# PCIE1_CORE_VMAP_MMRS register map
Vendor: Texas Instruments
Peripheral module from a debugger description file (folder J7VCL).
Registers are 32-bit, read-write, reset 0x0 unless marked. A register's access mark holds for its fields unless they carry their own. Offsets are as the file gives them; lines under a group give offsets from that group; [hi:lo] are bit positions; {n}, {i} and the like mark numbered series; 'fields as' and 'values as' point back to an identical list; <NAME> marks a mode.

## PCIE1_CORE_VMAP_MMRS
0x00 PCIE_VMAP_CTRL_j — Control register Offset = 0h + (j * Ch); where j = 0h to 1Fh
  [0] EN — ID enable
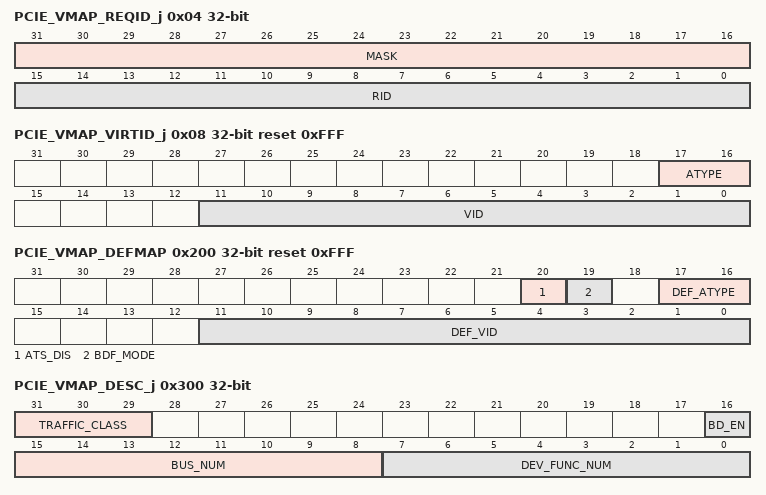
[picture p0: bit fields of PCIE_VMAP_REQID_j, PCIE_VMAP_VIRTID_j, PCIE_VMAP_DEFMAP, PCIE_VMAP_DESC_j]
0x04 PCIE_VMAP_REQID_j — Requester ID mask and value register Offset = 4h + (j * Ch); where j = 0h to 1Fh
  [31:16] MASK — RequesterID mask
  [15:0] RID — RequesterID
0x08 PCIE_VMAP_VIRTID_j reset 0xFFF — Virt ID and Atype register Offset = 8h + (j * Ch); where j = 0h to 1Fh
  [17:16] ATYPE — Address type attribute.
  [11:0] VID — Match ID
0x200 PCIE_VMAP_DEFMAP reset 0xFFF — virtID default value register
  [20] ATS_DIS — ATS mode.
  [19] BDF_MODE — Bus default mode.
  [17:16] DEF_ATYPE — Default address type attribute.
  [11:0] DEF_VID — Default match ID
0x300 PCIE_VMAP_DESC_j access per field — Return to the . Outbound ASEL non-zero descriptor register Offset = 300h + (j * 4h); where j = 0h to 1Fh
  [31:29] TRAFFIC_CLASS rw — PCIe Traffic Class (TC) associated with the non-zero ASEL request.
  [16] BD_EN rw — External bus and device number enable.This bit enables the client to supply the bus and device numbers to be used in the requester ID. If this bit is 0, the core uses the captured values of the bus and device numbers to form the Requester ID. If this bit is 1, the core uses the bus and device numbers supplied by the client on dev_func_num[7:4] and bus_num[15:8] to form the Requester ID. This bit must always be set while originating requests in the RP mode, and the corresponding Requester ID must be placed on dev_func_num[7:4] and bus_num[15:8].
  [15:8] BUS_NUM rw — PCI Bus Number associated with the request.When descriptor bit[16] is set, this field must specify the bus number to be used for the Requester ID. Otherwise, this field is ignored by the core.
  [7:0] DEV_FUNC_NUM rw — PCI Function and Device Number associated with the request.In ARI mode, all 8 bits are used to indicate the requesting function number. In legacy mode, only bits[3:0] are used to specify function number and bits[7:4] are used to specify the device number to be used within the Requester ID, if the descriptor bit[16] is set. If the descriptor bit[16] is not set, then bits[7:4] are ignored.
0x400 PCIE_VMAP_OB_VIRTID_MATCH access per field — Return to the . Outbound virtid match register
  [11:5] VAL rw — Outbound virtid [11:5] match value.When outbound VBUSM slave interface virtid [11:5] matches the value in this register and the ASEL value is non-zero, the PCIe controller address translation unit (ATU) is bypassed. The PCIe TLP descriptor values are taken from the ext_desc registers.
